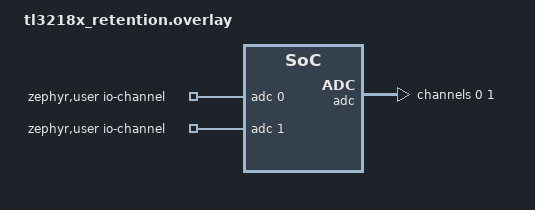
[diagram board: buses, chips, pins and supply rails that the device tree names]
/*
 * SPDX-License-Identifier: Apache-2.0
 *
 * Copyright (c) 2026 Telink Semiconductor (Shanghai) Co., Ltd.
 */

/ {
	zephyr,user {
		/* adjust channel number according to pinmux in board.dts */
		io-channels = <&adc 0>, <&adc 1>;
	};
};

&adc {
	#address-cells = <1>;
	#size-cells = <0>;

	channel@0 {
		reg = <0>;
		zephyr,gain = "ADC_GAIN_1_4";
		zephyr,reference = "ADC_REF_INTERNAL";
		zephyr,acquisition-time = <ADC_ACQ_TIME(ADC_ACQ_TIME_TICKS, 20)>;
		zephyr,resolution = <12>;
		zephyr,input-positive = <DT_ADC_GPIO_PB1>;
		zephyr,input-negative = <DT_ADC_GND>;
		zephyr,oversampling = <8>;
	};

	channel@1 {
		reg = <1>;
		zephyr,gain = "ADC_GAIN_1";
		zephyr,reference = "ADC_REF_INTERNAL";
		zephyr,acquisition-time = <ADC_ACQ_TIME_DEFAULT>;
		zephyr,resolution = <12>;
		zephyr,input-positive = <DT_ADC_VBAT_1_4>;
		zephyr,input-negative = <DT_ADC_GND>;
		zephyr,oversampling = <8>;
	};
};
